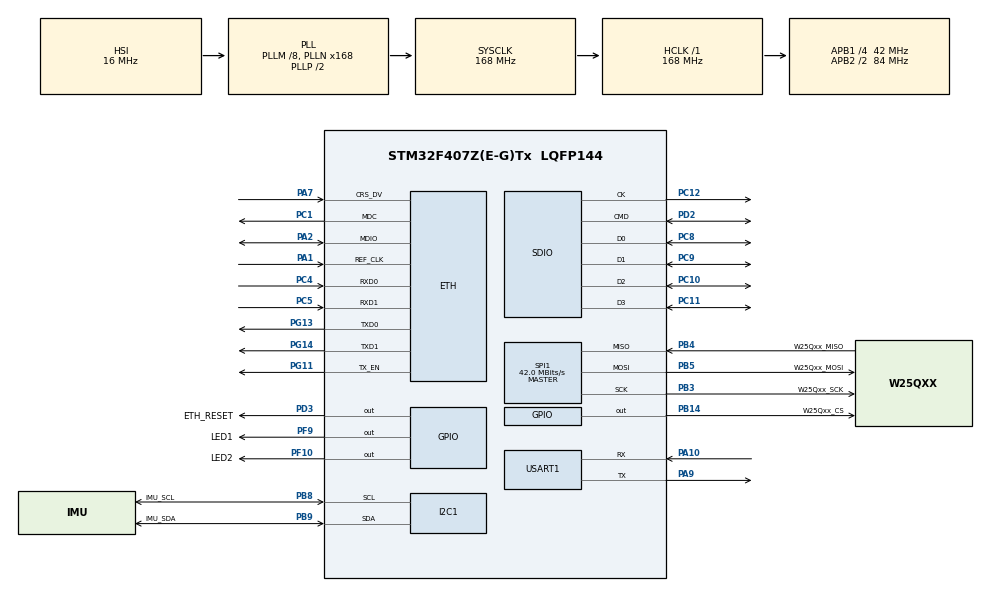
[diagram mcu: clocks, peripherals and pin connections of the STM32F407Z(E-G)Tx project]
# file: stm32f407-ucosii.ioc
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Dma.Request0=SDIO_TX
Dma.Request1=SDIO_RX
Dma.SDIO_RX.1.Direction=DMA_PERIPH_TO_MEMORY
Dma.SDIO_RX.1.FIFOMode=DMA_FIFOMODE_ENABLE
Dma.SDIO_RX.1.FIFOThreshold=DMA_FIFO_THRESHOLD_FULL
Dma.SDIO_RX.1.Instance=DMA2_Stream6
Dma.SDIO_RX.1.MemBurst=DMA_MBURST_INC4
Dma.SDIO_RX.1.MemDataAlignment=DMA_MDATAALIGN_WORD
Dma.SDIO_RX.1.MemInc=DMA_MINC_ENABLE
Dma.SDIO_RX.1.Mode=DMA_PFCTRL
Dma.SDIO_RX.1.PeriphBurst=DMA_PBURST_INC4
Dma.SDIO_RX.1.PeriphDataAlignment=DMA_PDATAALIGN_WORD
Dma.SDIO_RX.1.PeriphInc=DMA_PINC_DISABLE
Dma.SDIO_RX.1.Priority=DMA_PRIORITY_LOW
Dma.SDIO_TX.0.Direction=DMA_MEMORY_TO_PERIPH
Dma.SDIO_TX.0.FIFOMode=DMA_FIFOMODE_ENABLE
Dma.SDIO_TX.0.FIFOThreshold=DMA_FIFO_THRESHOLD_FULL
Dma.SDIO_TX.0.Instance=DMA2_Stream3
Dma.SDIO_TX.0.MemBurst=DMA_MBURST_INC4
Dma.SDIO_TX.0.MemDataAlignment=DMA_MDATAALIGN_WORD
Dma.SDIO_TX.0.MemInc=DMA_MINC_ENABLE
Dma.SDIO_TX.0.Mode=DMA_PFCTRL
Dma.SDIO_TX.0.PeriphBurst=DMA_PBURST_INC4
Dma.SDIO_TX.0.PeriphDataAlignment=DMA_PDATAALIGN_WORD
Dma.SDIO_TX.0.PeriphInc=DMA_PINC_DISABLE
Dma.SDIO_TX.0.Priority=DMA_PRIORITY_LOW
ETH.MediaInterface=ETH_MEDIA_INTERFACE_RMII
ETH.PHY_Name_RMII=userPHY
ETH.PHY_SR=31
ETH.PHY_User_Name=LAN8720A
ETH.PhyAddress=0
FATFS.USE_DMA_CODE_SD=1
I2C1.I2C_Mode=I2C_Fast
Mcu.Family=STM32F4
Mcu.Name=STM32F407Z(E-G)Tx
Mcu.Package=LQFP144
NVIC.DMA2_Stream3_IRQn=true\:0\:0\:false\:false\:true\:false\:true
NVIC.DMA2_Stream6_IRQn=true\:0\:0\:false\:false\:true\:false\:true
NVIC.PriorityGroup=NVIC_PRIORITYGROUP_4
NVIC.SDIO_IRQn=true\:0\:0\:false\:false\:true\:true\:true
NVIC.USART1_IRQn=true\:0\:0\:false\:false\:true\:true\:true
PA1.Mode=RMII
PA1.Signal=ETH_REF_CLK
PA10.Mode=Asynchronous
PA10.Signal=USART1_RX
PA13.Mode=Serial_Wire
PA13.Signal=SYS_JTMS-SWDIO
PA14.Mode=Serial_Wire
PA14.Signal=SYS_JTCK-SWCLK
PA2.Mode=RMII
PA2.Signal=ETH_MDIO
PA7.Mode=RMII
PA7.Signal=ETH_CRS_DV
PA9.Mode=Asynchronous
PA9.Signal=USART1_TX
PB14.GPIO_Label=W25Qxx_CS
PB14.Signal=GPIO_Output
PB3.GPIO_Label=W25Qxx_SCK
PB3.Mode=Full_Duplex_Master
PB3.Signal=SPI1_SCK
PB4.GPIO_Label=W25Qxx_MISO
PB4.Mode=Full_Duplex_Master
PB4.Signal=SPI1_MISO
PB5.GPIO_Label=W25Qxx_MOSI
PB5.Mode=Full_Duplex_Master
PB5.Signal=SPI1_MOSI
PB8.GPIO_Label=IMU_SCL
PB8.Mode=I2C
PB8.Signal=I2C1_SCL
PB9.GPIO_Label=IMU_SDA
PB9.Mode=I2C
PB9.Signal=I2C1_SDA
PC1.Mode=RMII
PC1.Signal=ETH_MDC
PC10.Mode=SD_4_bits_Wide_bus
PC10.Signal=SDIO_D2
PC11.Mode=SD_4_bits_Wide_bus
PC11.Signal=SDIO_D3
PC12.Mode=SD_4_bits_Wide_bus
PC12.Signal=SDIO_CK
PC4.Mode=RMII
PC4.Signal=ETH_RXD0
PC5.Mode=RMII
PC5.Signal=ETH_RXD1
PC8.Mode=SD_4_bits_Wide_bus
PC8.Signal=SDIO_D0
PC9.Mode=SD_4_bits_Wide_bus
PC9.Signal=SDIO_D1
PD2.Mode=SD_4_bits_Wide_bus
PD2.Signal=SDIO_CMD
PD3.GPIO_Label=ETH_RESET
PD3.Signal=GPIO_Output
PF10.GPIO_Label=LED2
PF10.Signal=GPIO_Output
PF9.GPIO_Label=LED1
PF9.Signal=GPIO_Output
PG11.Mode=RMII
PG11.Signal=ETH_TX_EN
PG13.Mode=RMII
PG13.Signal=ETH_TXD0
PG14.Mode=RMII
PG14.Signal=ETH_TXD1
ProjectManager.HeapSize=0x10000
ProjectManager.StackSize=0x400
ProjectManager.TargetToolchain=MDK-ARM V5.27
RCC.48MHZClocksFreq_Value=48000000
RCC.AHBFreq_Value=168000000
RCC.APB1CLKDivider=RCC_HCLK_DIV4
RCC.APB1Freq_Value=42000000
RCC.APB1TimFreq_Value=84000000
RCC.APB2CLKDivider=RCC_HCLK_DIV2
RCC.APB2Freq_Value=84000000
RCC.APB2TimFreq_Value=168000000
RCC.CortexFreq_Value=168000000
RCC.HCLKFreq_Value=168000000
RCC.HSE_VALUE=25000000
RCC.HSI_VALUE=16000000
RCC.LSE_VALUE=32768
RCC.PLLM=8
RCC.PLLN=168
RCC.PLLQ=7
RCC.SYSCLKFreq_VALUE=168000000
RCC.SYSCLKSource=RCC_SYSCLKSOURCE_PLLCLK
RCC.VCOOutputFreq_Value=336000000
SPI1.BaudRatePrescaler=SPI_BAUDRATEPRESCALER_2
SPI1.CalculateBaudRate=42.0 MBits/s
SPI1.Direction=SPI_DIRECTION_2LINES
SPI1.Mode=SPI_MODE_MASTER
SPI1.VirtualType=VM_MASTER
USART1.VirtualMode=VM_ASYNC
VP_FATFS_VS_SDIO.Mode=SDIO
VP_RNG_VS_RNG.Mode=RNG_Activate
VP_RTC_VS_RTC_Activate.Mode=RTC_Enabled
board=custom

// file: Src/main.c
/* USER CODE BEGIN Header */
/**
  ******************************************************************************
  * @file           : main.c
  * @brief          : Main program body
  ******************************************************************************
  * @attention
  *
  * <h2><center>&copy; Copyright (c) 2020 STMicroelectronics.
  * All rights reserved.</center></h2>
  *
  * This software component is licensed by ST under BSD 3-Clause license,
  * the "License"; You may not use this file except in compliance with the
  * License. You may obtain a copy of the License at:
  *                        opensource.org/licenses/BSD-3-Clause
  *
  ******************************************************************************
  */
/* USER CODE END Header */

#include "main.h"
#include "dma.h"
#include "eth.h"
#include "fatfs.h"
#include "i2c.h"
#include "rng.h"
#include "rtc.h"
#include "sdio.h"
#include "spi.h"
#include "usart.h"
#include "gpio.h"

/* USER CODE BEGIN Includes */
#include "app_main.h"
/* USER CODE END Includes */

void SystemClock_Config(void);

int main(void)
{

  /* MCU Configuration--------------------------------------------------------*/

  /* Reset of all peripherals, Initializes the Flash interface and the Systick. */
  HAL_Init();

  /* Configure the system clock */
  SystemClock_Config();

  /* Initialize all configured peripherals */
  MX_GPIO_Init();
  MX_SPI1_Init();
  MX_USART1_UART_Init();
  MX_ETH_Init();
  MX_RNG_Init();
  MX_RTC_Init();
  MX_SDIO_SD_Init();
  MX_DMA_Init();
  MX_I2C1_Init();
  MX_FATFS_Init();
  /* USER CODE BEGIN 2 */
  OS_CPU_SysTickInitFreq(HAL_RCC_GetHCLKFreq());

  OSInit();
  create_app_task();
  OSStart();
  /* USER CODE END 2 */

  /* Infinite loop */
  while (1)
  {

  }
}

void SystemClock_Config(void)
{
  RCC_OscInitTypeDef RCC_OscInitStruct = {0};
  RCC_ClkInitTypeDef RCC_ClkInitStruct = {0};
  RCC_PeriphCLKInitTypeDef PeriphClkInitStruct = {0};

  /** Configure the main internal regulator output voltage
  */
  __HAL_RCC_PWR_CLK_ENABLE();
  __HAL_PWR_VOLTAGESCALING_CONFIG(PWR_REGULATOR_VOLTAGE_SCALE1);
  /** Initializes the CPU, AHB and APB busses clocks
  */
  RCC_OscInitStruct.OscillatorType = RCC_OSCILLATORTYPE_HSI|RCC_OSCILLATORTYPE_LSI;
  RCC_OscInitStruct.HSIState = RCC_HSI_ON;
  RCC_OscInitStruct.HSICalibrationValue = RCC_HSICALIBRATION_DEFAULT;
  RCC_OscInitStruct.LSIState = RCC_LSI_ON;
  RCC_OscInitStruct.PLL.PLLState = RCC_PLL_ON;
  RCC_OscInitStruct.PLL.PLLSource = RCC_PLLSOURCE_HSI;
  RCC_OscInitStruct.PLL.PLLM = 8;
  RCC_OscInitStruct.PLL.PLLN = 168;
  RCC_OscInitStruct.PLL.PLLP = RCC_PLLP_DIV2;
  RCC_OscInitStruct.PLL.PLLQ = 7;
  if (HAL_RCC_OscConfig(&RCC_OscInitStruct) != HAL_OK)
  {
    Error_Handler();
  }
  /** Initializes the CPU, AHB and APB busses clocks
  */
  RCC_ClkInitStruct.ClockType = RCC_CLOCKTYPE_HCLK|RCC_CLOCKTYPE_SYSCLK
                              |RCC_CLOCKTYPE_PCLK1|RCC_CLOCKTYPE_PCLK2;
  RCC_ClkInitStruct.SYSCLKSource = RCC_SYSCLKSOURCE_PLLCLK;
  RCC_ClkInitStruct.AHBCLKDivider = RCC_SYSCLK_DIV1;
  RCC_ClkInitStruct.APB1CLKDivider = RCC_HCLK_DIV4;
  RCC_ClkInitStruct.APB2CLKDivider = RCC_HCLK_DIV2;

  if (HAL_RCC_ClockConfig(&RCC_ClkInitStruct, FLASH_LATENCY_5) != HAL_OK)
  {
    Error_Handler();
  }
  PeriphClkInitStruct.PeriphClockSelection = RCC_PERIPHCLK_RTC;
  PeriphClkInitStruct.RTCClockSelection = RCC_RTCCLKSOURCE_LSI;
  if (HAL_RCCEx_PeriphCLKConfig(&PeriphClkInitStruct) != HAL_OK)
  {
    Error_Handler();
  }
}

void Error_Handler(void)
{
}

/************************ (C) COPYRIGHT STMicroelectronics *****END OF FILE****/
